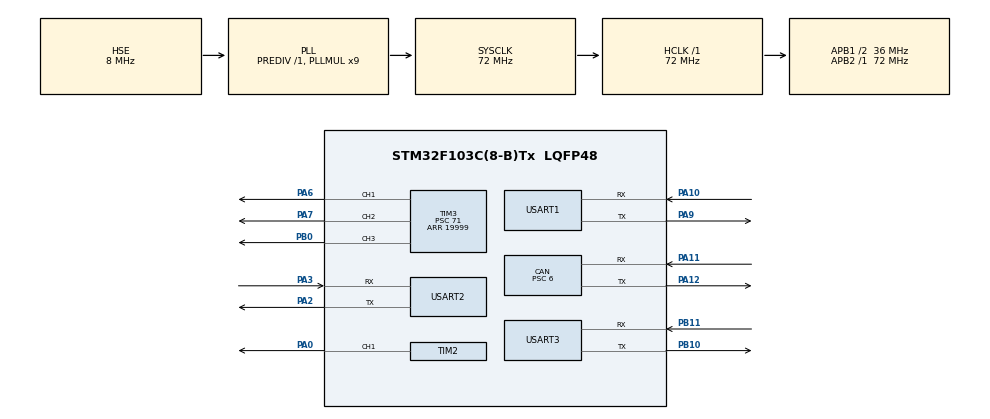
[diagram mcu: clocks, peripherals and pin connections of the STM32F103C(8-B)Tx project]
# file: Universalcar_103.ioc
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CAN.ABOM=ENABLE
CAN.BS1=CAN_BS1_9TQ
CAN.BS2=CAN_BS2_2TQ
CAN.CalculateBaudRate=499999
CAN.CalculateTimeBit=2000
CAN.CalculateTimeQuantum=166.66666666666669
CAN.NART=ENABLE
CAN.Prescaler=6
FREERTOS.INCLUDE_vTaskDelayUntil=1
FREERTOS.Tasks01=receiveTask,1,512,ReceiveTask,As weak,NULL,Dynamic,NULL,NULL;imuTask,2,384,ImuTask,As weak,NULL,Dynamic,NULL,NULL;chassisTask,0,256,ChassisTask,As weak,NULL,Dynamic,NULL,NULL;gimbalTask,0,256,GimbalTask,As weak,NULL,Dynamic,NULL,NULL
FREERTOS.configIDLE_SHOULD_YIELD=0
FREERTOS.configTOTAL_HEAP_SIZE=12288
Mcu.Family=STM32F1
Mcu.Name=STM32F103C(8-B)Tx
Mcu.Package=LQFP48
NVIC.PriorityGroup=NVIC_PRIORITYGROUP_4
NVIC.TIM4_IRQn=true\:15\:0\:false\:false\:true\:false\:false\:true\:true
NVIC.TimeBase=TIM4_IRQn
NVIC.TimeBaseIP=TIM4
NVIC.USART1_IRQn=true\:5\:0\:true\:false\:true\:true\:true\:true\:true
NVIC.USART2_IRQn=true\:5\:0\:true\:false\:true\:true\:true\:true\:true
NVIC.USART3_IRQn=true\:5\:0\:true\:false\:true\:true\:true\:true\:true
NVIC.USB_LP_CAN1_RX0_IRQn=true\:5\:0\:true\:false\:true\:true\:true\:true\:true
PA0-WKUP.Signal=S_TIM2_CH1_ETR
PA10.Mode=Asynchronous
PA10.Signal=USART1_RX
PA11.Mode=CAN_Activate
PA11.Signal=CAN_RX
PA12.Mode=CAN_Activate
PA12.Signal=CAN_TX
PA13.Mode=Serial_Wire
PA13.Signal=SYS_JTMS-SWDIO
PA14.Mode=Serial_Wire
PA14.Signal=SYS_JTCK-SWCLK
PA2.Mode=Asynchronous
PA2.Signal=USART2_TX
PA3.Mode=Asynchronous
PA3.Signal=USART2_RX
PA6.Signal=S_TIM3_CH1
PA7.Signal=S_TIM3_CH2
PA9.Mode=Asynchronous
PA9.Signal=USART1_TX
PB0.Signal=S_TIM3_CH3
PB10.Mode=Asynchronous
PB10.Signal=USART3_TX
PB11.Mode=Asynchronous
PB11.Signal=USART3_RX
PD0-OSC_IN.Mode=HSE-External-Oscillator
PD0-OSC_IN.Signal=RCC_OSC_IN
PD1-OSC_OUT.Mode=HSE-External-Oscillator
PD1-OSC_OUT.Signal=RCC_OSC_OUT
ProjectManager.HeapSize=0x200
ProjectManager.StackSize=0x400
ProjectManager.TargetToolchain=MDK-ARM V5.32
RCC.AHBFreq_Value=72000000
RCC.APB1CLKDivider=RCC_HCLK_DIV2
RCC.APB1Freq_Value=36000000
RCC.APB1TimFreq_Value=72000000
RCC.APB2Freq_Value=72000000
RCC.APB2TimFreq_Value=72000000
RCC.HCLKFreq_Value=72000000
RCC.PLLMUL=RCC_PLL_MUL9
RCC.PLLSourceVirtual=RCC_PLLSOURCE_HSE
RCC.SYSCLKFreq_VALUE=72000000
RCC.SYSCLKSource=RCC_SYSCLKSOURCE_PLLCLK
RCC.USBFreq_Value=72000000
SH.S_TIM2_CH1_ETR.0=TIM2_CH1,PWM Generation1 CH1
SH.S_TIM3_CH1.0=TIM3_CH1,PWM Generation1 CH1
SH.S_TIM3_CH2.0=TIM3_CH2,PWM Generation2 CH2
SH.S_TIM3_CH3.0=TIM3_CH3,PWM Generation3 CH3
TIM2.Channel-PWM\ Generation1\ CH1=TIM_CHANNEL_1
TIM2.Period=239
TIM2.Prescaler=99
TIM3.Channel-PWM\ Generation1\ CH1=TIM_CHANNEL_1
TIM3.Channel-PWM\ Generation2\ CH2=TIM_CHANNEL_2
TIM3.Channel-PWM\ Generation3\ CH3=TIM_CHANNEL_3
TIM3.Period=19999
TIM3.Prescaler=71
TIM3.Pulse-PWM\ Generation1\ CH1=500
TIM3.Pulse-PWM\ Generation2\ CH2=500
TIM3.Pulse-PWM\ Generation3\ CH3=500
USART1.VirtualMode=VM_ASYNC
USART2.VirtualMode=VM_ASYNC
USART3.VirtualMode=VM_ASYNC
VP_FREERTOS_VS_CMSIS_V1.Mode=CMSIS_V1
VP_SYS_VS_tim4.Mode=TIM4
VP_TIM2_VS_ClockSourceINT.Mode=Internal
VP_TIM3_VS_ClockSourceINT.Mode=Internal
board=custom

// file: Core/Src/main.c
/* USER CODE BEGIN Header */
/**
  ******************************************************************************
  * @file           : main.c
  * @brief          : Main program body
  ******************************************************************************
  * @attention
  *
  * Copyright (c) 2026 STMicroelectronics.
  * All rights reserved.
  *
  * This software is licensed under terms that can be found in the LICENSE file
  * in the root directory of this software component.
  * If no LICENSE file comes with this software, it is provided AS-IS.
  *
  ******************************************************************************
  */
/* USER CODE END Header */
#include "main.h"
#include "cmsis_os.h"
#include "can.h"
#include "tim.h"
#include "usart.h"
#include "gpio.h"

/* USER CODE BEGIN Includes */
#include "header.h"
/* USER CODE END Includes */

void SystemClock_Config(void);
void MX_FREERTOS_Init(void);

int main(void)
{

  /* MCU Configuration--------------------------------------------------------*/

  /* Reset of all peripherals, Initializes the Flash interface and the Systick. */
  HAL_Init();

  /* Configure the system clock */
  SystemClock_Config();

  /* Initialize all configured peripherals */
  MX_GPIO_Init();
  MX_CAN_Init();
  MX_TIM2_Init();
  MX_TIM3_Init();
  MX_USART1_UART_Init();
  MX_USART2_UART_Init();
  MX_USART3_UART_Init();
  /* USER CODE BEGIN 2 */
#if MOTOR_USE_UART
  /* 串口电机：USART1 已由 MX_USART1_UART_Init 初始化并在 usart.c 里开了接收中断，
     这里只复位电机反馈解析状态机 */
  ZdtUart_Init();
#else
  /* 配置 CAN 过滤器 + 启动 CAN + 打开 FIFO0 接收中断（必须在 osKernelStart 之前） */
  ZdtCan_Init();
#endif

  /* 补光灯 PWM：原来只在 BLE 初始化里启动，BLE 关闭后会漏掉，这里显式启动一次 */
  Led_Init();
  /* USER CODE END 2 */

  /* Call init function for freertos objects (in cmsis_os2.c) */
  MX_FREERTOS_Init();

  /* Start scheduler */
  osKernelStart();

  /* We should never get here as control is now taken by the scheduler */

  /* Infinite loop */
  while (1)
  {

  }
}

void SystemClock_Config(void)
{
  RCC_OscInitTypeDef RCC_OscInitStruct = {0};
  RCC_ClkInitTypeDef RCC_ClkInitStruct = {0};

  /** Initializes the RCC Oscillators according to the specified parameters
  * in the RCC_OscInitTypeDef structure.
  */
  RCC_OscInitStruct.OscillatorType = RCC_OSCILLATORTYPE_HSE;
  RCC_OscInitStruct.HSEState = RCC_HSE_ON;
  RCC_OscInitStruct.HSEPredivValue = RCC_HSE_PREDIV_DIV1;
  RCC_OscInitStruct.HSIState = RCC_HSI_ON;
  RCC_OscInitStruct.PLL.PLLState = RCC_PLL_ON;
  RCC_OscInitStruct.PLL.PLLSource = RCC_PLLSOURCE_HSE;
  RCC_OscInitStruct.PLL.PLLMUL = RCC_PLL_MUL9;
  if (HAL_RCC_OscConfig(&RCC_OscInitStruct) != HAL_OK)
  {
    Error_Handler();
  }

  /** Initializes the CPU, AHB and APB buses clocks
  */
  RCC_ClkInitStruct.ClockType = RCC_CLOCKTYPE_HCLK|RCC_CLOCKTYPE_SYSCLK
                              |RCC_CLOCKTYPE_PCLK1|RCC_CLOCKTYPE_PCLK2;
  RCC_ClkInitStruct.SYSCLKSource = RCC_SYSCLKSOURCE_PLLCLK;
  RCC_ClkInitStruct.AHBCLKDivider = RCC_SYSCLK_DIV1;
  RCC_ClkInitStruct.APB1CLKDivider = RCC_HCLK_DIV2;
  RCC_ClkInitStruct.APB2CLKDivider = RCC_HCLK_DIV1;

  if (HAL_RCC_ClockConfig(&RCC_ClkInitStruct, FLASH_LATENCY_2) != HAL_OK)
  {
    Error_Handler();
  }
}

void HAL_TIM_PeriodElapsedCallback(TIM_HandleTypeDef *htim)
{
  if (htim->Instance == TIM4)
  {
    HAL_IncTick();
  }
}

void Error_Handler(void)
{
  __disable_irq();
  while (1)
  {
  }
}

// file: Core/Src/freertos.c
/* USER CODE BEGIN Header */
/**
  ******************************************************************************
  * File Name          : freertos.c
  * Description        : Code for freertos applications
  ******************************************************************************
  * @attention
  *
  * Copyright (c) 2026 STMicroelectronics.
  * All rights reserved.
  *
  * This software is licensed under terms that can be found in the LICENSE file
  * in the root directory of this software component.
  * If no LICENSE file comes with this software, it is provided AS-IS.
  *
  ******************************************************************************
  */
/* USER CODE END Header */

#include "FreeRTOS.h"
#include "task.h"
#include "main.h"
#include "cmsis_os.h"

osThreadId receiveTaskHandle;
osThreadId imuTaskHandle;
osThreadId chassisTaskHandle;
osThreadId gimbalTaskHandle;

void ReceiveTask(void const * argument);
void ImuTask(void const * argument);
void ChassisTask(void const * argument);
void GimbalTask(void const * argument);

void MX_FREERTOS_Init(void); /* (MISRA C 2004 rule 8.1) */

/* GetIdleTaskMemory prototype (linked to static allocation support) */
void vApplicationGetIdleTaskMemory( StaticTask_t **ppxIdleTaskTCBBuffer, StackType_t **ppxIdleTaskStackBuffer, uint32_t *pulIdleTaskStackSize );

/* USER CODE BEGIN GET_IDLE_TASK_MEMORY */
static StaticTask_t xIdleTaskTCBBuffer;
static StackType_t xIdleStack[configMINIMAL_STACK_SIZE];

void vApplicationGetIdleTaskMemory( StaticTask_t **ppxIdleTaskTCBBuffer, StackType_t **ppxIdleTaskStackBuffer, uint32_t *pulIdleTaskStackSize )
{
  *ppxIdleTaskTCBBuffer = &xIdleTaskTCBBuffer;
  *ppxIdleTaskStackBuffer = &xIdleStack[0];
  *pulIdleTaskStackSize = configMINIMAL_STACK_SIZE;
  /* place for user code */
}
/* USER CODE END GET_IDLE_TASK_MEMORY */

void MX_FREERTOS_Init(void) {

  /* Create the thread(s) */
  /* definition and creation of receiveTask */
  osThreadDef(receiveTask, ReceiveTask, osPriorityAboveNormal, 0, 512);
  receiveTaskHandle = osThreadCreate(osThread(receiveTask), NULL);

  /* definition and creation of imuTask */
  osThreadDef(imuTask, ImuTask, osPriorityHigh, 0, 384);
  imuTaskHandle = osThreadCreate(osThread(imuTask), NULL);

  /* definition and creation of chassisTask */
  osThreadDef(chassisTask, ChassisTask, osPriorityNormal, 0, 256);
  chassisTaskHandle = osThreadCreate(osThread(chassisTask), NULL);

  /* definition and creation of gimbalTask */
  osThreadDef(gimbalTask, GimbalTask, osPriorityNormal, 0, 256);
  gimbalTaskHandle = osThreadCreate(osThread(gimbalTask), NULL);

}

__weak void ReceiveTask(void const * argument)
{
  for(;;)
  {
    osDelay(1);
  }
}

__weak void ImuTask(void const * argument)
{
  for(;;)
  {
    osDelay(1);
  }
}

__weak void ChassisTask(void const * argument)
{
  for(;;)
  {
    osDelay(1);
  }
}

__weak void GimbalTask(void const * argument)
{
  for(;;)
  {
    osDelay(1);
  }
}
